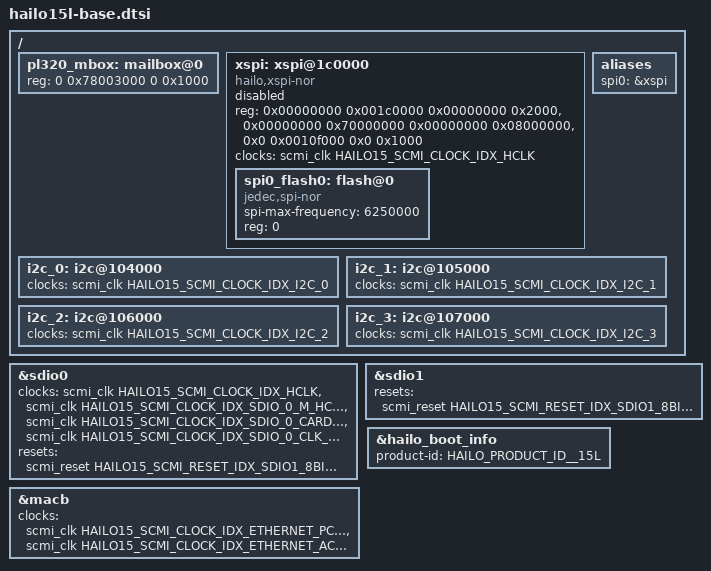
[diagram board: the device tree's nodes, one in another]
// SPDX-License-Identifier: GPL-2.0
/*
 * dts file for Hailo Hailo15 SoC
 *
 * Copyright (c) 2019-2024 Hailo Technologies Ltd. All rights reserved.
 */

#define HAILO_SOC_TYPE HAILO_SOC_HAILO15L
#include "hailo1x-base.dtsi"

/ {
    pl320_mbox: mailbox@0 {
        reg = <0 0x78003000 0 0x1000>;
    };

    xspi: xspi@1c0000 {
        compatible = "hailo,xspi-nor";
        #address-cells = <1>;
        #size-cells = <0>;
        reg = <0x00000000 0x001c0000 0x00000000 0x2000>,
                <0x00000000 0x70000000 0x00000000 0x08000000>,
                <0x0 0x0010f000 0x0 0x1000>;

        clocks = <&scmi_clk HAILO15_SCMI_CLOCK_IDX_HCLK>;

        status = "disabled";

        u-boot,dm-spl;

        spi0_flash0: flash@0 {
            #address-cells = <1>;
            #size-cells = <1>;
            compatible = "jedec,spi-nor";
            spi-max-frequency = <6250000>; /* 90Mhz in DTR, 166Mhz in STR */
            reg = <0>;        /* chip select */

            u-boot,dm-spl;
        };
    };

    aliases {
        spi0 = &xspi;
    };

    i2c_0: i2c@104000 {
        clocks = <&scmi_clk HAILO15_SCMI_CLOCK_IDX_I2C_0>;
    };

    i2c_1: i2c@105000 {
        clocks = <&scmi_clk HAILO15_SCMI_CLOCK_IDX_I2C_1>;
    };

    i2c_2: i2c@106000 {
        clocks = <&scmi_clk HAILO15_SCMI_CLOCK_IDX_I2C_2>;
    };

    i2c_3: i2c@107000 {
        clocks = <&scmi_clk HAILO15_SCMI_CLOCK_IDX_I2C_3>;
    };
};

&sdio0 {
    clocks = <&scmi_clk HAILO15_SCMI_CLOCK_IDX_HCLK>, <&scmi_clk HAILO15_SCMI_CLOCK_IDX_SDIO_0_M_HCLK>,
             <&scmi_clk HAILO15_SCMI_CLOCK_IDX_SDIO_0_CARD_CLK>, <&scmi_clk HAILO15_SCMI_CLOCK_IDX_SDIO_0_CLK_DIV_BYPASS>;
    clock-names = "core", "m_clk", "card_clk", "clk_div_bypass";
    resets = <&scmi_reset HAILO15_SCMI_RESET_IDX_SDIO1_8BIT_MUX>;
    reset-names = "sdio1-8bit-mux";
};

&sdio1 {
    resets = <&scmi_reset HAILO15_SCMI_RESET_IDX_SDIO1_8BIT_MUX>;
    reset-names = "sdio1-8bit-mux";
};

&macb {
    clocks = <&scmi_clk HAILO15_SCMI_CLOCK_IDX_ETHERNET_PCLK>, <&scmi_clk HAILO15_SCMI_CLOCK_IDX_ETHERNET_ACLK>;
    clock-names = "pclk", "hclk";
};

&hailo_boot_info {
    product-id = <HAILO_PRODUCT_ID__15L>;
};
